# ECC_AGGR_ECC_AGGR_53010000h register map
Vendor: Texas Instruments
Peripheral module from a debugger description file (folder AM263P).
Registers are 32-bit, access not given, reset 0x0 unless marked. A register's access mark holds for its fields unless they carry their own. Offsets are as the file gives them; lines under a group give offsets from that group; [hi:lo] are bit positions; {n}, {i} and the like mark numbered series; 'fields as' and 'values as' point back to an identical list; <NAME> marks a mode.

## ECC_AGGR
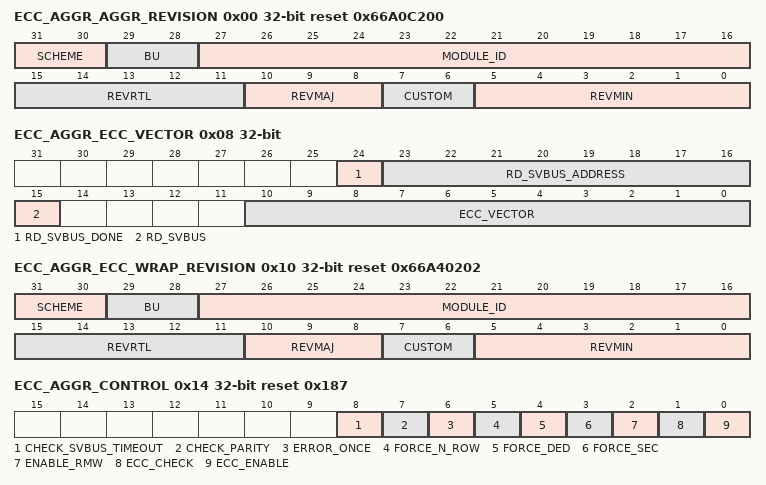
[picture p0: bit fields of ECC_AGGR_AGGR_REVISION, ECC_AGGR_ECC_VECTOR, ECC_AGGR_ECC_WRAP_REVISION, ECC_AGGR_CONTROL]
0x00 ECC_AGGR_AGGR_REVISION ro reset 0x66A0C200 — The Revision Register contains the major and minor revisions for the ECC aggregator module. It does not support byte accesses.
  [31:30] SCHEME
  [29:28] BU — Business unit
  [27:16] MODULE_ID
  [15:11] REVRTL — RTL version
  [10:8] REVMAJ — Major version
  [7:6] CUSTOM — Custom version
  [5:0] REVMIN — Minor version
0x08 ECC_AGGR_ECC_VECTOR — ECC RAM ID to select which ECC RAM to control or read status from.
  [24] RD_SVBUS_DONE ro — Status to indicate if read on serial bus is complete
  [23:16] RD_SVBUS_ADDRESS rw — Read address
  [15] RD_SVBUS — Trigger a read operation to the specified read address that requires a serial bus access. In normal operation, the trigger bit is only '1' for a single cycle and thus can not be read back. (access R/W1TS)
  [10:0] ECC_VECTOR rw — Value written to select the corresponding ECC RAM for control or status
0x0C ECC_AGGR_MISC_STATUS ro reset 0x9 — Contains misc status such as number of ECC RAMs serviced by the ECC aggregator.
  [10:0] NUM_RAMS — Indicates the number of RAMS serviced by the ECC aggregator
0x10 ECC_AGGR_ECC_WRAP_REVISION ro reset 0x66A40202 — Revision parameters.
  fields as ECC_AGGR_AGGR_REVISION
0x14 ECC_AGGR_CONTROL rw reset 0x187 — ECC Control Register.
  [8] CHECK_SVBUS_TIMEOUT — check for svbus timeout errors
  [7] CHECK_PARITY — check for parity errors
  [6] ERROR_ONCE — Force Error only once
  [5] FORCE_N_ROW — Force Error on any RAM read
  [4] FORCE_DED — Force Double Bit Error
  [3] FORCE_SEC — Force Single Bit Error
  [2] ENABLE_RMW
  [1] ECC_CHECK — Enable ECC check
  [0] ECC_ENABLE — Enable ECC
0x18 ECC_AGGR_ERROR_CTRL1 rw — ECC Error Control1 Register.
  [31:0] ECC_ROW — Row address where single or double-bit error needs to be applied. This is ignored if force_n_row is set
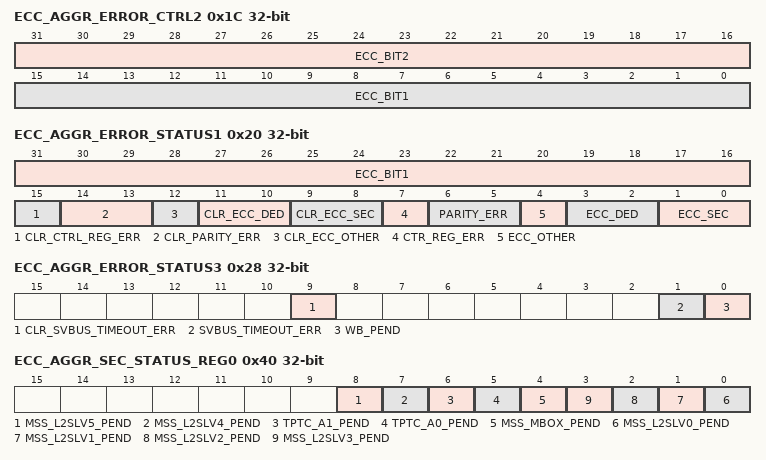
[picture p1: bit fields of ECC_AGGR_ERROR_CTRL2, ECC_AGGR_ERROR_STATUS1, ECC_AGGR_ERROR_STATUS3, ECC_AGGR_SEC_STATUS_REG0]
0x1C ECC_AGGR_ERROR_CTRL2 rw — ECC Error Control2 Register.
  [31:16] ECC_BIT2 — Data bit that needs to be flipped if double bit error needs to be forced
  [15:0] ECC_BIT1 — Data bit that needs to be flipped when force_sec is set
0x20 ECC_AGGR_ERROR_STATUS1 — ECC Error Status1 Register.
  [31:16] ECC_BIT1 ro — Data bit that corresponds to the single-bit error
  [15] CLR_CTRL_REG_ERR — Clear control reg error Error Status, you must also re write the control register itself to clear this (access R/W1TC)
  [14:13] CLR_PARITY_ERR — Clear parity Error Status (access R/WD)
  [12] CLR_ECC_OTHER — Clear other Error Status (access R/W1TC)
  [11:10] CLR_ECC_DED — Clear Double Bit Error Status (access R/WD)
  [9:8] CLR_ECC_SEC — Clear Single Bit Error Status (access R/WD)
  [7] CTR_REG_ERR — control register error pending, Level interrupt (access R/W1TS)
  [6:5] PARITY_ERR — Level parity error Error Status (access R/W1TS)
  [4] ECC_OTHER — Successive single-bit errors have occurred while a writeback is still pending, Level interrupt (access R/W1TS)
  [3:2] ECC_DED — Level Double Bit Error Status (access R/WI)
  [1:0] ECC_SEC — Level Single Bit Error Status (access R/WI)
0x24 ECC_AGGR_ERROR_STATUS2 ro — ECC Error Status2 Register.
  [31:0] ECC_ROW — Row address where the single or double-bit error has occurred
0x28 ECC_AGGR_ERROR_STATUS3 — ECC Error Status3 Register.
  [9] CLR_SVBUS_TIMEOUT_ERR — Clear svbus timeout Error Status (access R/W1TC)
  [1] SVBUS_TIMEOUT_ERR — Level svbus timeout error Error Status (access R/W1TS)
  [0] WB_PEND ro — delayed write back pending Status
0x3C ECC_AGGR_SEC_EOI_REG — EOI Register.
  [0] EOI_WR — Write of 1 to this register indicates that software has acknowledged the pending interrupt and the next interrupt can be sent to the host. The bit is self clearing and will be read as a zero. (access R/W1TS)
0x40 ECC_AGGR_SEC_STATUS_REG0 — Interrupt Status Register 0
  [8] MSS_L2SLV5_PEND — Interrupt Pending Status for mss_l2slv5_pend (access R/W1TS)
  [7] MSS_L2SLV4_PEND — Interrupt Pending Status for mss_l2slv4_pend (access R/W1TS)
  [6] TPTC_A1_PEND — Interrupt Pending Status for tptc_a1_pend (access R/W1TS)
  [5] TPTC_A0_PEND — Interrupt Pending Status for tptc_a0_pend (access R/W1TS)
  [4] MSS_MBOX_PEND — Interrupt Pending Status for mss_mbox_pend (access R/W1TS)
  [n] MSS_L2SLV{n}_PEND (n=0..3) — Interrupt Pending Status for mss_l2slv{n}_pend (access R/W1TS)
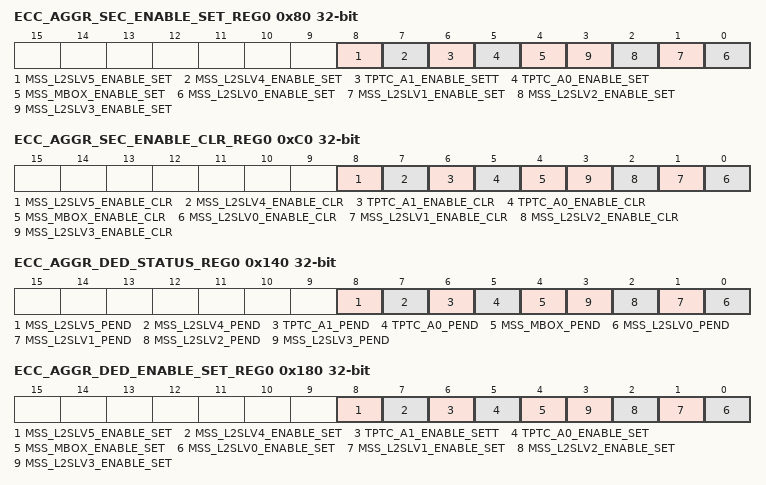
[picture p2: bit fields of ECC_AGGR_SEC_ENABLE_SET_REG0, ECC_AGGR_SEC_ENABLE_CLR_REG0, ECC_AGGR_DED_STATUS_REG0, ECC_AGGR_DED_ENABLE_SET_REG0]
0x80 ECC_AGGR_SEC_ENABLE_SET_REG0 — Interrupt Enable Set Register 0
  [8] MSS_L2SLV5_ENABLE_SET — Interrupt Enable Set Register for mss_l2slv5_pend (access R/W1TS)
  [7] MSS_L2SLV4_ENABLE_SET — Interrupt Enable Set Register for mss_l2slv4_pend (access R/W1TS)
  [6] TPTC_A1_ENABLE_SETT — Interrupt Enable Set Register for tptc_a1_pend (access R/W1TS)
  [5] TPTC_A0_ENABLE_SET — Interrupt Enable Set Register for tptc_a0_pend (access R/W1TS)
  [4] MSS_MBOX_ENABLE_SET — Interrupt Enable Set Register for mss_mbox_pend (access R/W1TS)
  [n] MSS_L2SLV{n}_ENABLE_SET (n=0..3) — Interrupt Enable Set Register for mss_l2slv{n}_pend (access R/W1TS)
0xC0 ECC_AGGR_SEC_ENABLE_CLR_REG0 — Interrupt Enable Clear Register 0
  [8] MSS_L2SLV5_ENABLE_CLR — Interrupt Enable Clear Register for mss_l2slv5_pend (access R/W1TC)
  [7] MSS_L2SLV4_ENABLE_CLR — Interrupt Enable Clear Register for mss_l2slv4_pend (access R/W1TC)
  [6] TPTC_A1_ENABLE_CLR — Interrupt Enable Clear Register for tptc_a1_pend (access R/W1TC)
  [5] TPTC_A0_ENABLE_CLR — Interrupt Enable Clear Register for tptc_a0_pend (access R/W1TC)
  [4] MSS_MBOX_ENABLE_CLR — Interrupt Enable Clear Register for mss_mbox_pend (access R/W1TC)
  [n] MSS_L2SLV{n}_ENABLE_CLR (n=0..3) — Interrupt Enable Clear Register for mss_l2slv{n}_pend (access R/W1TC)
0x13C ECC_AGGR_DED_EOI_REG — EOI Register.
  fields as ECC_AGGR_SEC_EOI_REG
0x140 ECC_AGGR_DED_STATUS_REG0 — Interrupt Status Register 0
  fields as ECC_AGGR_SEC_STATUS_REG0
0x180 ECC_AGGR_DED_ENABLE_SET_REG0 — Interrupt Enable Set Register 0
  fields as ECC_AGGR_SEC_ENABLE_SET_REG0
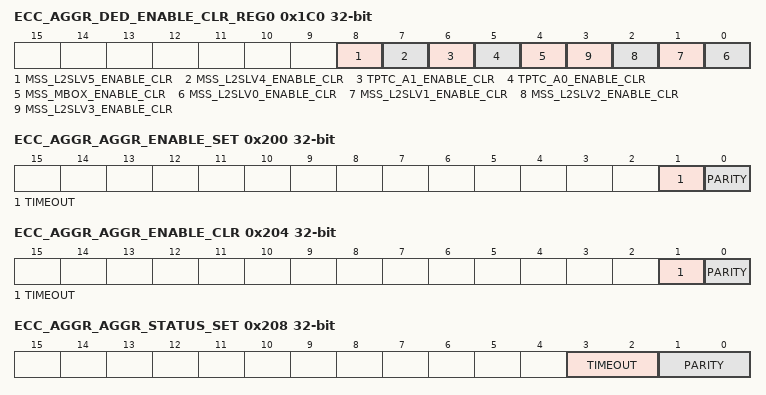
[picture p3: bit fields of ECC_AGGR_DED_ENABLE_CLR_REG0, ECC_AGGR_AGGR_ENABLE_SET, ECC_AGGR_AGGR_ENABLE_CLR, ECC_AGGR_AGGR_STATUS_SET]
0x1C0 ECC_AGGR_DED_ENABLE_CLR_REG0 — Interrupt Enable Clear Register 0
  fields as ECC_AGGR_SEC_ENABLE_CLR_REG0
0x200 ECC_AGGR_AGGR_ENABLE_SET — Enable set register for aggregator interrupts.
  [1] TIMEOUT — Interrupt enable set for svbus timeout errors (access R/W1TS)
  [0] PARITY — Interrupt enable set for parity errors (access R/W1TS)
0x204 ECC_AGGR_AGGR_ENABLE_CLR — Enable clear register for aggregator interrupts.
  [1] TIMEOUT — Interrupt enable clear for svbus timeout errors (access R/W1TC)
  [0] PARITY — Interrupt enable clear for parity errors (access R/W1TC)
0x208 ECC_AGGR_AGGR_STATUS_SET — Status set register for aggregator interrupts.
  [3:2] TIMEOUT — 2-bit saturating counter of the number of timeout errors that have occurred since last cleared. 2'b00 - No timeout errors have occurred 2'b01 - 1 timeout error has occurred 2'b10 - 2 timeout error has occurred 2'b11 - 3 or more timeout errors have occurred A write of a non-zero value to this register increments that many from the timeout fields. If the value written is less than the current value of the counter, then the pending level interrupt stays asserted. . If this register goes from 0 ot non zero a level interrupt will be asserted as well as a pulse interrupt. If the value was non zero to non zero then the level interrupt would remain asserted, but no new pulse interrupt would be asserted. You must write the eoi register to get a new pulse interrupt. (access R/WI)
  [1:0] PARITY — 2-bit saturating counter of the number of parity errors that have occurred since last cleared. 2'b00 - No parity errors have occurred 2'b01 - 1 parity error has occurred 2'b10 - 2 parity error has occurred 2'b11 - 3 or more parity error have occurred A write of a non-zero value to this register incrments that many from the parity fields. If the value written is less than the current value of the counter, then the pending level interrupt stays asserted. If this register goes from 0 ot non zero a level interrupt will be asserted as well as a pulse interrupt. If the value was non zero to non zero then the level interrupt would remain asserted, but no new pulse interrupt would be asserted. You must write the eoi register to get a new pulse interrupt. (access R/WI)
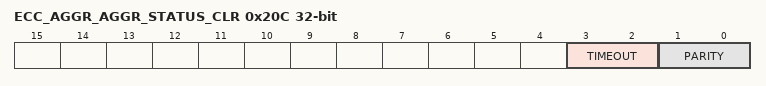
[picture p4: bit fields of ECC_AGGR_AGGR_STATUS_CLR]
0x20C ECC_AGGR_AGGR_STATUS_CLR — Status clear register for aggregator interrupts.
  [3:2] TIMEOUT — 2'b00 - No timeout errors have occurred 2'b01 - 1 timeout error has occurred 2'b10 - 2 timeout error has occurred 2'b11 - 3 or more timeout errors have occurred A write of a non-zero value to this register decrements that many from the timeout fields. If the resulting written value is non zero, then the pending level interrupt stays asserted. A new pulse interrupt will nto be asserted, you must write the eoi register for that to occur. If you write a value more than the counter value the result will be zero. (access R/WD)
  [1:0] PARITY — 2'b00 - No parity errors have occurred 2'b01 - 1 parity error has occurred 2'b10 - 2 parity error has occurred 2'b11 - 3 or more parity error have occurred A write of a non-zero value to this register decrements that many from the parity fields. If the resulting written value is non zero, then the pending level interrupt stays asserted. A new pulse interrupt will nto be asserted, you must write the eoi register for that to occur. If you write a value more than the counter value the result will be zero. (access R/WD)
